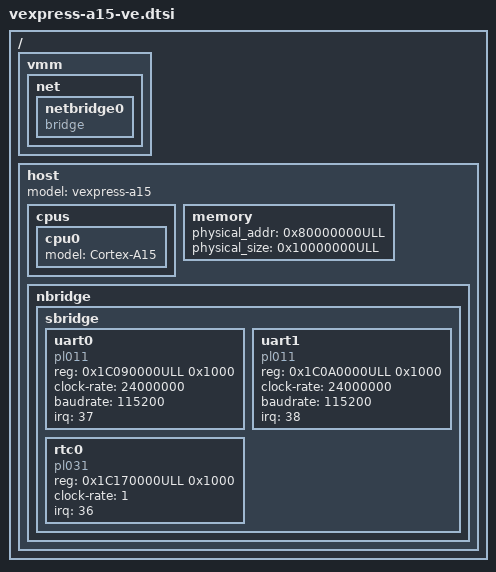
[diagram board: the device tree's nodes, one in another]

/ {
	vmm {
		net {
			netbridge0 {
				device_type = "netswitch";
				compatible = "bridge";
			};
		};
	};

	host {
		model = "vexpress-a15";
		device_type = "host";
		
		cpus {
			cpu0 {
				device_type = "cpu";
				model = "Cortex-A15";
			};
		};

		memory {
			/* NOTE: By default QEMU will only proivde 128 MB 
			 * unless specified by "-m" option. If you have
			 * X MB then we will be able to access only first
			 * X MB starting at physical_addr.
			 */
			physical_addr = <0x80000000ULL>;
			physical_size = <0x10000000ULL>; /* 256 MB */
		};

		nbridge {
			sbridge {
				#address-cells = <2>;
				#size-cells = <1>;

				uart0 {
			      		device_type = "serial";
			      		compatible = "pl011";
			      		reg = <0x1C090000ULL 0x1000>;
					clock-rate = <24000000>;
			      		baudrate = <115200>;
					irq = <37>;
				};

				uart1 {
			      		device_type = "serial";
			      		compatible = "pl011";
			      		reg = <0x1C0A0000ULL 0x1000>;
					clock-rate = <24000000>;
			      		baudrate = <115200>;
					irq = <38>;
				};

				rtc0 {
			      		device_type = "rtc";
			      		compatible = "pl031";
			      		reg = <0x1C170000ULL 0x1000>;
					clock-rate = <1>;
					irq = <36>;
				};
			};
		};
	};
};
